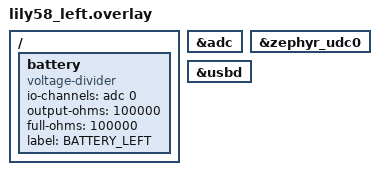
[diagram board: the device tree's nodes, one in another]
&adc {
    status = "okay";
};

&zephyr_udc0 {
    status = "okay";
};

&usbd {
    status = "okay";
};

/ {
    battery: battery {
        compatible = "voltage-divider";
        io-channels = <&adc 0>;
        output-ohms = <100000>;
        full-ohms = <100000>;
        label = "BATTERY_LEFT";
        status = "okay";
    };
};
